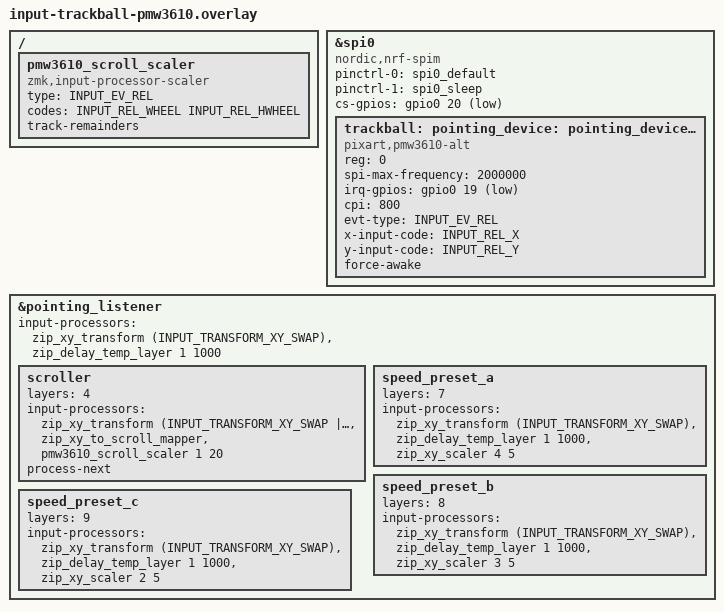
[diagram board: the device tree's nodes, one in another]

#include <dt-bindings/zmk/input_transform.h>

/ {
    pmw3610_scroll_scaler: pmw3610_scroll_scaler {
        compatible = "zmk,input-processor-scaler";
        #input-processor-cells = <2>;
        type = <INPUT_EV_REL>;
        codes = <INPUT_REL_WHEEL INPUT_REL_HWHEEL>;
        track-remainders;
    };
};

&spi0 {
    status = "okay";
    compatible = "nordic,nrf-spim";
    pinctrl-0 = <&spi0_default>;
    pinctrl-1 = <&spi0_sleep>;
    pinctrl-names = "default", "sleep";
    cs-gpios = <&gpio0 20 GPIO_ACTIVE_LOW>;

    trackball: pointing_device: pointing_device@0 {
        status = "okay";
        compatible = "pixart,pmw3610-alt";
        reg = <0>;
        spi-max-frequency = <2000000>;
        irq-gpios = <&gpio0 19 (GPIO_ACTIVE_LOW | GPIO_PULL_UP)>;
        cpi = <800>;
        evt-type = <INPUT_EV_REL>;
        x-input-code = <INPUT_REL_X>;
        y-input-code = <INPUT_REL_Y>;
        force-awake;
    };
};

&pointing_listener {
    input-processors =
        <&zip_xy_transform (INPUT_TRANSFORM_XY_SWAP)>,
        <&zip_delay_temp_layer 1 1000>;

    scroller {
        layers = <4>;
        input-processors =
            <&zip_xy_transform (INPUT_TRANSFORM_XY_SWAP | INPUT_TRANSFORM_Y_INVERT)>,
            <&zip_xy_to_scroll_mapper>,
            <&pmw3610_scroll_scaler 1 20>;
        process-next;
    };

    /* 速度プリセットでは zip_delay_temp_layer を zip_xy_scaler より「前」に置く。
       後ろに置くと縮小後の移動量で activation-distance を判定してしまい、
       プリセットが遅いほどマウスレイヤーに入りにくくなる */
    speed_preset_a {
        layers = <7>;
        input-processors =
            <&zip_xy_transform (INPUT_TRANSFORM_XY_SWAP)>,
            <&zip_delay_temp_layer 1 1000>,
            <&zip_xy_scaler 4 5>;
    };

    speed_preset_b {
        layers = <8>;
        input-processors =
            <&zip_xy_transform (INPUT_TRANSFORM_XY_SWAP)>,
            <&zip_delay_temp_layer 1 1000>,
            <&zip_xy_scaler 3 5>;
    };

    speed_preset_c {
        layers = <9>;
        input-processors =
            <&zip_xy_transform (INPUT_TRANSFORM_XY_SWAP)>,
            <&zip_delay_temp_layer 1 1000>,
            <&zip_xy_scaler 2 5>;
    };
};
